# PIC32MX430F064L device description
Architecture: MIPS; Family: PIC32MX; Series: PIC32MX
Registers are 32-bit, read-write, no defined reset value unless marked. A register's access mark holds for its fields unless they carry their own. Offsets are from the block's base; [hi:lo] are bit positions; {n}, {i} and the like mark numbered series.

## PMP
Instances: PMP 0x1f807000 in periph0
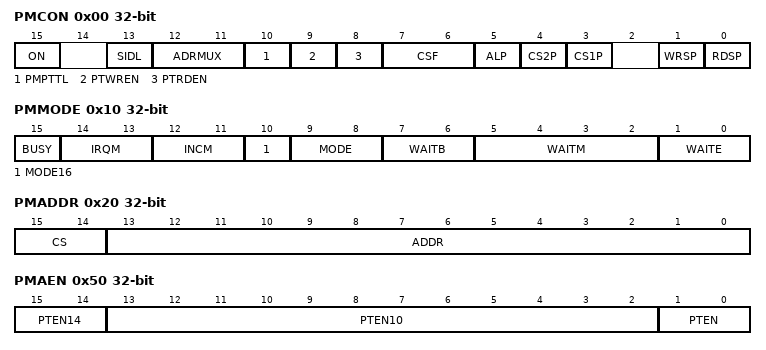
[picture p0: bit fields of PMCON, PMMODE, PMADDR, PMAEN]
0x00 PMCON — Parallel Port Control Register
  [15] ON — Parallel Master Port Enable bit
    1=PMP is enabled; 0=PMP is disabled
  [13] SIDL — Stop in Idle Mode bit
    1=Discontinue module operation when device enters Idle mode; 0=Continue module operation in Idle mode
  [12:11] ADRMUX — Address/Data Multiplexing Selection bits
    3=Lower 8 bits of address are multiplexed on PMD(15:0) pins; 2=All 16 bits of address are multiplexed on PMD(7:0) pins; 1=Lower 8 bits of address are multiplexed on PMD(7:0) pins; 0=Address and data appear on separate pins
  [10] PMPTTL — PMP Module TTL Input Buffer Select bit
    1=PMP module uses TTL input buffers; 0=PMP module uses Schmitt Trigger input buffer
  [9] PTWREN — Write Enable Strobe Port Enable bit
    1=PMWR/PMENB port is enabled; 0=PMWR/PMENB port is disabled
  [8] PTRDEN — Read/Write Strobe Port Enable bit
    1=PMRD/PMWR port is enabled; 0=PMRD/PMWR port is disabled
  [7:6] CSF — Chip Select Function bits
    2=PMCS1 and PMCS2 function as Chip Select; 1=PMCS1 functions as address bit 14; PMCS2 functions as Chip Select; 0=PMCS1 and PMCS2 function as address bits 14 and 15
  [5] ALP — Address Latch Polarity bit
    1=Active-high (PMALL and PMALH); 0=Active-low (PMALL and PMALH)
  [4] CS2P — Chip Select 0 Polarity bit
    1=Active-high (PMCS2); 0=Active-low (PMCS2)
  [3] CS1P — Chip Select 0 Polarity bit
    1=Active-high (PMCS1); 0=Active-low (PMCS1)
  [1] WRSP — Write Strobe Polarity bit
    1=(If MODE(1:0) = 00/01/10) Write strobe active-high / (If MODE(1:0) = 11) Enable strobe active-high; 0=(If MODE(1:0) = 00/01/10) Write strobe active-low / (If MODE(1:0) = 11) Enable strobe active-low
  [0] RDSP — Read Strobe Polarity bit
    1=(If MODE(1:0) = 00/01/10) Read Strobe active-high / (If MODE(1:0) = 11) Read/write strobe active-high; 0=(If MODE(1:0) = 00/01/10) Read Strobe active-low / (If MODE(1:0) = 11) Read/write strobe active-low
0x10 PMMODE — Parallel Port Mode Register
  [15] BUSY — Busy bit (Master mode only)
    1=Port is busy; 0=Port is not busy
  [14:13] IRQM — Interrupt Request Mode bits
    2=Interrupt generated when Read Buffer 3 is read or Write Buffer 3 is written (Buffered PSP mode) or on a read or write operation when PMA(1:0) =11 (Addressable Slave mode only); 1=Interrupt generated at the end of the read/write cycle; 0=No Interrupt generated
  [12:11] INCM — Increment Mode bits
    3=Slave mode read and write buffers auto-increment (MODE(1:0) = 00 only); 2=Decrement ADDR(15:0) by 1 every read/write cycle; 1=Increment ADDR(15:0) by 1 every read/write cycle; 0=No increment or decrement of address
  [10] MODE16 — 8/16-bit Mode bit
    1=16-bit mode: a read or write to the data register invokes a single 16-bit transfer; 0=8-bit mode: a read or write to the data register invokes a single 8-bit transfer
  [9:8] MODE — Parallel Port Mode Select bits
    3=Master mode 1 (PMCSx; 2=Master mode 2 (PMCSx; 1=Enhanced Slave mode; 0=Legacy Parallel Slave Port
  [7:6] WAITB — Data Setup to Read/Write Strobe Wait States bits
    3=Data wait of 4 TPB; multiplexed address phase of 4 TPB; 2=Data wait of 3 TPB; multiplexed address phase of 3 TPB; 1=Data wait of 2 TPB; multiplexed address phase of 2 TPB; 0=Data wait of 1 TPB; multiplexed address phase of 1 TPB (default)
  [5:2] WAITM — Data Read/Write Strobe Wait States bits
    {v}=Wait of {v+1}TPB (v=1..15); 0=Wait of 1TPB (default)
  [1:0] WAITE — Data Hold After Read/Write Strobe Wait States bits
    3=(for write operations) Wait of 4 TPB / (for read operations) Wait of 3 TPB; 2=(for write operations) Wait of 3 TPB / (for read operations) Wait of 2 TPB; 1=(for write operations) Wait of 2 TPB / (for read operations) Wait of 1 TPB; 0=(for write operations) Wait of 1 TPB (default) / (for read operations) Wait of 0 TPB (default)
0x20 PMADDR — Parallel Port Address Register
  [15:14] CS
  [13:0] ADDR — Address bits
    0=address is 0; 0x3fff=address is 0x3fff
0x30 PMDOUT
  [31:0] DATAOUT
0x40 PMDIN
  [31:0] DATAIN
0x50 PMAEN — Parallel Port Pin Enable Register
  [15:14] PTEN14 — PMCS1 Address Port Enable bit
    3=PMCS1; 0=PMCS1 functions as port I/O
  [13:2] PTEN10 — PMP Address Port Enable bits
    0xfff=PMA(13:2) function as PMP address lines; 0=PMA(13:2) function as port I/O
  [1:0] PTEN — PMALH/PMALL Port Enable bits
    3=PMA1 and PMA0 function as either PMA(1:0) or PMALH and PMALL; 0=PMA1 and PMA0 pads function as port I/O
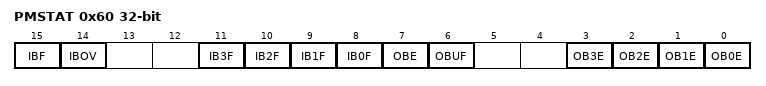
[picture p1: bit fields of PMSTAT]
0x60 PMSTAT — Parallel Port Status Register (Slave modes only)
  [15] IBF — Input Buffer Full Status bit
    1=All writable input buffer registers are full; 0=Some or all of the writable input buffer registers are empty
  [14] IBOV — Input Buffer Overflow Status bit
    1=A write attempt to a full input byte buffer occurred (must be cleared in software); 0=No overflow occurred
  [n+8] IB{n}F (n=0..3)
  [7] OBE — Output Buffer Empty Status bit
    1=All readable output buffer registers are empty; 0=Some or all of the readable output buffer registers are full
  [6] OBUF — Output Buffer Underflow Status bit
    1=A read occurred from an empty output byte buffer (must be cleared in software); 0=No underflow occurred
  [n] OB{n}E (n=0..3)
Value list PMADDR__CS1: 1=Chip Select 1 is active; 0=Chip Select 1 is inactive
Value list PMADDR__CS2: 1=Chip Select 2 is active; 0=Chip Select 2 is inactive
